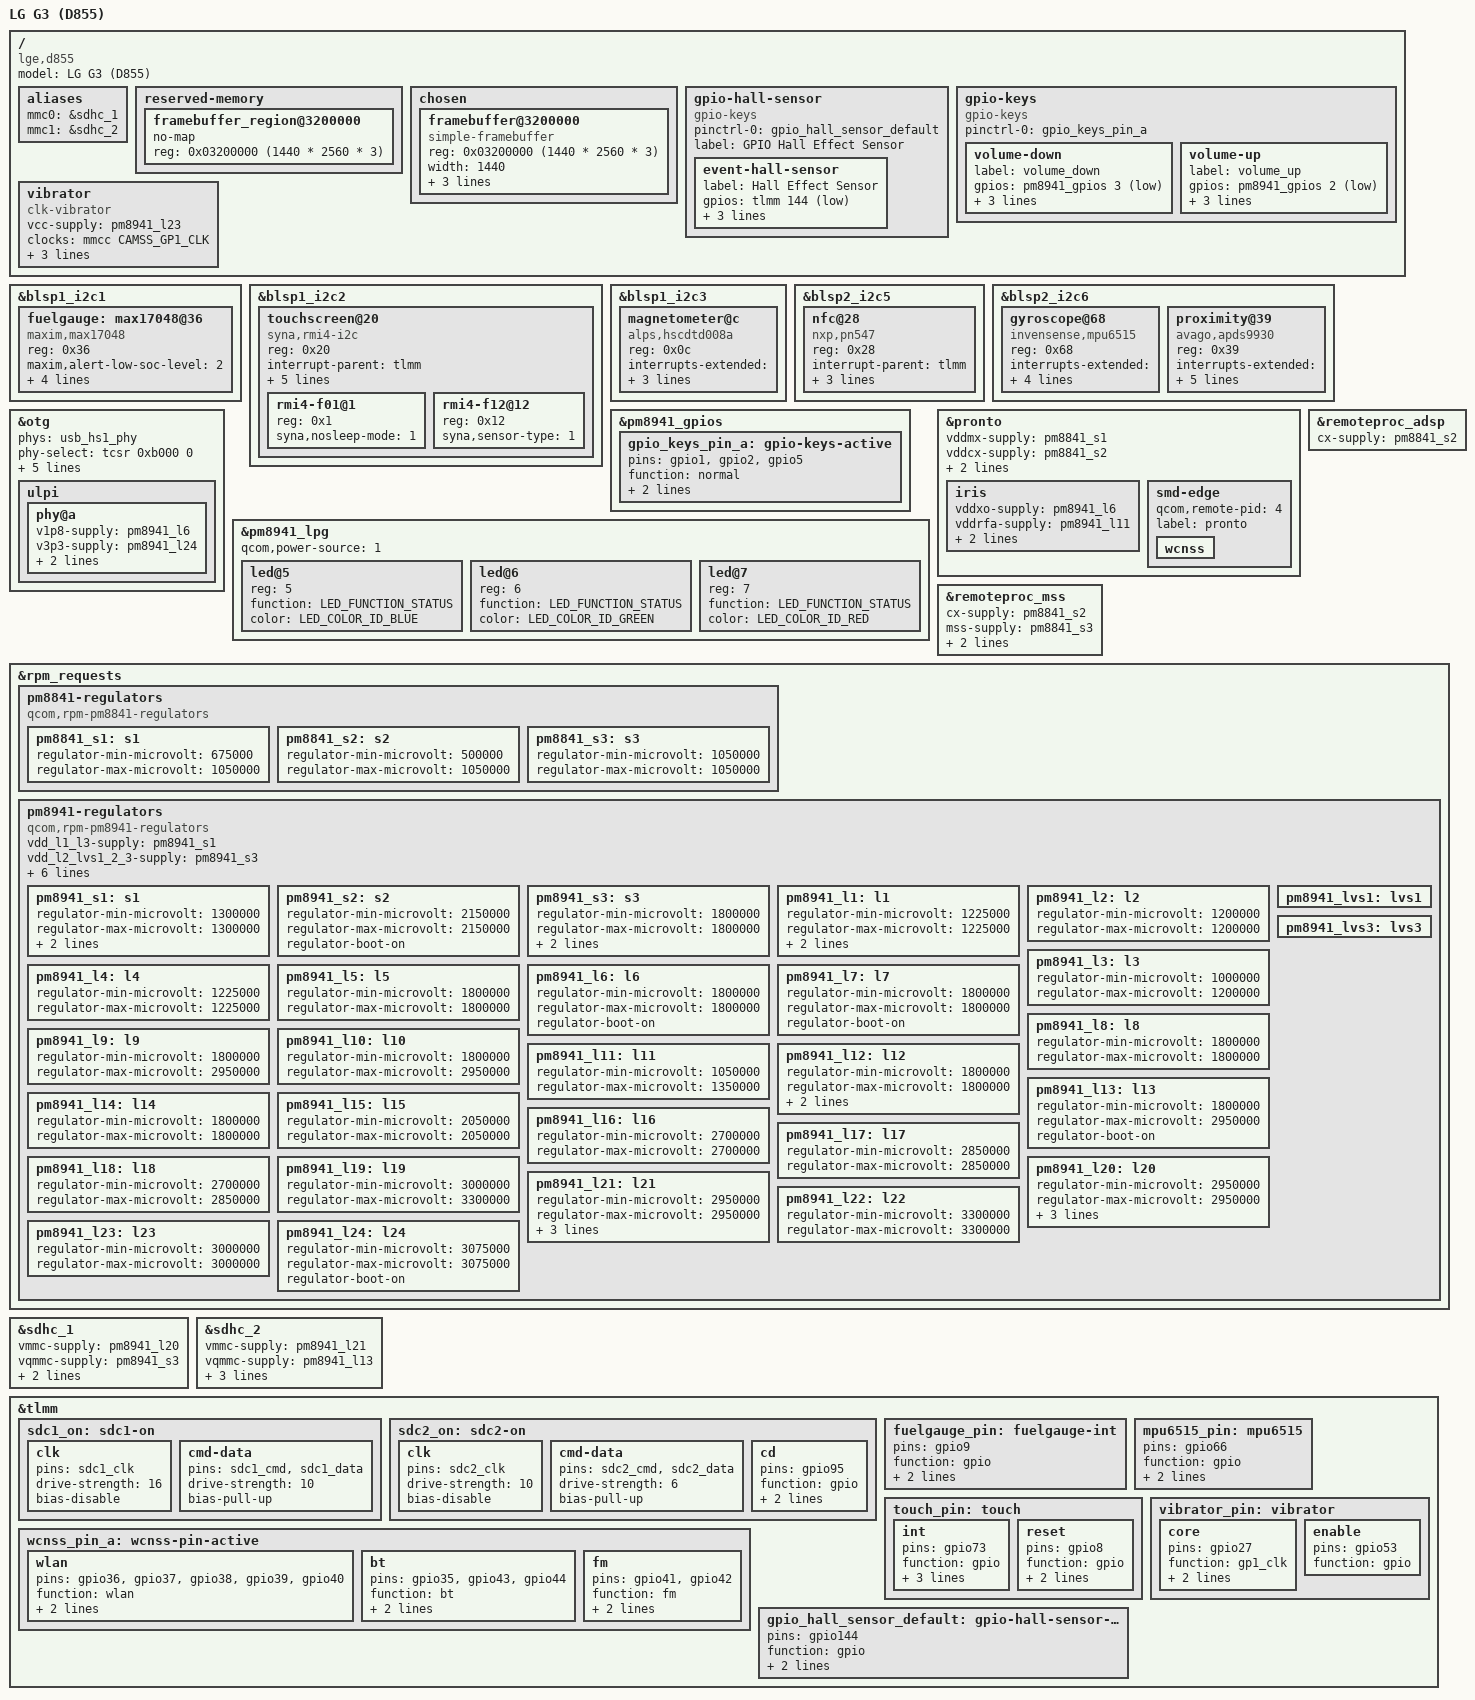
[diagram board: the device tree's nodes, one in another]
// SPDX-License-Identifier: GPL-2.0
#include "qcom-msm8974pro.dtsi"
#include "qcom-pm8841.dtsi"
#include "qcom-pm8941.dtsi"
#include <dt-bindings/input/input.h>
#include <dt-bindings/leds/common.h>
#include <dt-bindings/pinctrl/qcom,pmic-gpio.h>

/ {
	model = "LG G3 (D855)";
	compatible = "lge,d855", "qcom,msm8974";

	aliases {
		mmc0 = &sdhc_1;
		mmc1 = &sdhc_2;
	};

	reserved-memory {
		#address-cells = <1>;
		#size-cells = <1>;
		ranges;

		framebuffer_region@3200000 {
			no-map;
			reg = <0x03200000 (1440 * 2560 * 3)>;
		};
	};

	chosen {
		#address-cells = <1>;
		#size-cells = <1>;
		ranges;

		framebuffer@3200000 {
			compatible = "simple-framebuffer";
			reg = <0x03200000 (1440 * 2560 * 3)>;
			width = <1440>;
			height = <2560>;
			stride = <(1440 * 3)>;
			format = "r8g8b8";
		};
	};

	gpio-hall-sensor {
		compatible = "gpio-keys";

		pinctrl-names = "default";
		pinctrl-0 = <&gpio_hall_sensor_default>;

		label = "GPIO Hall Effect Sensor";

		event-hall-sensor {
			label = "Hall Effect Sensor";
			gpios = <&tlmm 144 GPIO_ACTIVE_LOW>;
			linux,input-type = <EV_SW>;
			linux,code = <SW_LID>;
			linux,can-disable;
		};
	};

	gpio-keys {
		compatible = "gpio-keys";

		pinctrl-names = "default";
		pinctrl-0 = <&gpio_keys_pin_a>;

		volume-down {
			label = "volume_down";
			gpios = <&pm8941_gpios 3 GPIO_ACTIVE_LOW>;
			linux,code = <KEY_VOLUMEDOWN>;
			wakeup-source;
			debounce-interval = <15>;
		};

		volume-up {
			label = "volume_up";
			gpios = <&pm8941_gpios 2 GPIO_ACTIVE_LOW>;
			linux,code = <KEY_VOLUMEUP>;
			wakeup-source;
			debounce-interval = <15>;
		};
	};

	vibrator {
		compatible = "clk-vibrator";

		vcc-supply = <&pm8941_l23>;

		clocks = <&mmcc CAMSS_GP1_CLK>;
		clock-names = "core";
		clock-frequency = <29813>;

		enable-gpios = <&tlmm 53 GPIO_ACTIVE_HIGH>;

		pinctrl-names = "default";
		pinctrl-0 = <&vibrator_pin>;
	};
};

&blsp1_i2c1 {
	status = "okay";

	fuelgauge: max17048@36 {
		compatible = "maxim,max17048";
		reg = <0x36>;
		maxim,alert-low-soc-level = <2>;
		maxim,double-soc;
		maxim,rcomp = /bits/ 8 <0x67>;

		interrupts-extended = <&tlmm 9 IRQ_TYPE_LEVEL_LOW>;

		pinctrl-names = "default";
		pinctrl-0 = <&fuelgauge_pin>;
	};
};

&blsp1_i2c2 {
	status = "okay";

	touchscreen@20 {
		compatible = "syna,rmi4-i2c";
		reg = <0x20>;

		interrupt-parent = <&tlmm>;
		interrupts = <73 IRQ_TYPE_EDGE_FALLING>;

		vdd-supply = <&pm8941_l22>;
		vio-supply = <&pm8941_lvs3>;
		
		syna,startup-delay-ms = <10>;

		pinctrl-names = "default";
		pinctrl-0 = <&touch_pin>;

		#address-cells = <1>;
		#size-cells = <0>;

		rmi4-f01@1 {
			reg = <0x1>;
			syna,nosleep-mode = <1>;
		};

		rmi4-f12@12 {
			reg = <0x12>;
			syna,sensor-type = <1>;
		};
	};
};

&blsp1_i2c3 {
	status = "okay";

	magnetometer@c {
		compatible = "alps,hscdtd008a";
		reg = <0x0c>;
		interrupts-extended = <&tlmm 67 IRQ_TYPE_EDGE_RISING>;
		dvdd-supply = <&pm8941_lvs1>;
		avdd-supply = <&pm8941_l17>;

		/* Add mount matrix here */
	};
};

&blsp2_i2c5 {
	status = "okay";

	nfc@28 {
		compatible = "nxp,pn547", "nxp,nxp-nci-i2c";

		reg = <0x28>;

		interrupt-parent = <&tlmm>;
		interrupts = <5 IRQ_TYPE_EDGE_RISING>;

		enable-gpios = <&tlmm 94 GPIO_ACTIVE_HIGH>;
		firmware-gpios = <&tlmm 92 GPIO_ACTIVE_HIGH>;
	};
};

&blsp2_i2c6 {
	status = "okay";

	#address-cells = <1>;
	#size-cells = <0>;

	gyroscope@68 {
		compatible = "invensense,mpu6515";
		reg = <0x68>;
		interrupts-extended = <&tlmm 66 IRQ_TYPE_EDGE_FALLING>;
		vddio-supply = <&pm8941_lvs1>;
		vdd-supply = <&pm8941_l17>;

		pinctrl-names = "default";
		pinctrl-0 = <&mpu6515_pin>;

		/* Add mount matrix here */
	};

	proximity@39 {
		compatible = "avago,apds9930";
		reg = <0x39>;
		interrupts-extended = <&tlmm 102 IRQ_TYPE_EDGE_FALLING>;
		vddio-supply = <&pm8941_lvs1>;
		vdd-supply = <&pm8941_l17>;
		led-max-microamp = <100000>;
		amstaos,proximity-diodes = <1>;
	};
};

&otg {
	status = "okay";

	phys = <&usb_hs1_phy>;
	phy-select = <&tcsr 0xb000 0>;
	extcon = <&smbb>, <&usb_id>;
	vbus-supply = <&chg_otg>;

	hnp-disable;
	srp-disable;
	adp-disable;

	ulpi {
		phy@a {
			status = "okay";

			v1p8-supply = <&pm8941_l6>;
			v3p3-supply = <&pm8941_l24>;

			extcon = <&smbb>;
			qcom,init-seq = /bits/ 8 <0x1 0x64>;
		};
	};
};

&pm8941_gpios {
	gpio_keys_pin_a: gpio-keys-active {
		pins = "gpio1", "gpio2", "gpio5";
		function = "normal";

		bias-pull-up;
		power-source = <PM8941_GPIO_S3>;
	};
};

&pm8941_lpg {
	status = "okay";

	#address-cells = <1>;
	#size-cells = <0>;

	qcom,power-source = <1>;

	led@5 {
		reg = <5>;
		function = LED_FUNCTION_STATUS;
		color = <LED_COLOR_ID_BLUE>;
	};

	led@6 {
		reg = <6>;
		function = LED_FUNCTION_STATUS;
		color = <LED_COLOR_ID_GREEN>;
	};

	led@7 {
		reg = <7>;
		function = LED_FUNCTION_STATUS;
		color = <LED_COLOR_ID_RED>;
	};
};

&pronto {
	status = "okay";

	vddmx-supply = <&pm8841_s1>;
	vddcx-supply = <&pm8841_s2>;
	vddpx-supply = <&pm8941_s3>;

	pinctrl-names = "default";
	pinctrl-0 = <&wcnss_pin_a>;

	iris {
		vddxo-supply = <&pm8941_l6>;
		vddrfa-supply = <&pm8941_l11>;
		vddpa-supply = <&pm8941_l19>;
		vdddig-supply = <&pm8941_s3>;
	};

	smd-edge {
		qcom,remote-pid = <4>;
		label = "pronto";

		wcnss {
			status = "okay";
		};
	};
};

&remoteproc_adsp {
	status = "okay";
	cx-supply = <&pm8841_s2>;
};

&remoteproc_mss {
	status = "okay";
	cx-supply = <&pm8841_s2>;
	mss-supply = <&pm8841_s3>;
	mx-supply = <&pm8841_s1>;
	pll-supply = <&pm8941_l12>;
};

&rpm_requests {
	pm8841-regulators {
		compatible = "qcom,rpm-pm8841-regulators";

		pm8841_s1: s1 {
			regulator-min-microvolt = <675000>;
			regulator-max-microvolt = <1050000>;
		};

		pm8841_s2: s2 {
			regulator-min-microvolt = <500000>;
			regulator-max-microvolt = <1050000>;
		};

		pm8841_s3: s3 {
			regulator-min-microvolt = <1050000>;
			regulator-max-microvolt = <1050000>;
		};
	};

	pm8941-regulators {
		compatible = "qcom,rpm-pm8941-regulators";

		vdd_l1_l3-supply = <&pm8941_s1>;
		vdd_l2_lvs1_2_3-supply = <&pm8941_s3>;
		vdd_l4_l11-supply = <&pm8941_s1>;
		vdd_l5_l7-supply = <&pm8941_s2>;
		vdd_l6_l12_l14_l15-supply = <&pm8941_s2>;
		vdd_l9_l10_l17_l22-supply = <&vreg_boost>;
		vdd_l13_l20_l23_l24-supply = <&vreg_boost>;
		vdd_l21-supply = <&vreg_boost>;

		pm8941_s1: s1 {
			regulator-min-microvolt = <1300000>;
			regulator-max-microvolt = <1300000>;
			regulator-always-on;
			regulator-boot-on;
		};

		pm8941_s2: s2 {
			regulator-min-microvolt = <2150000>;
			regulator-max-microvolt = <2150000>;
			regulator-boot-on;
		};

		pm8941_s3: s3 {
			regulator-min-microvolt = <1800000>;
			regulator-max-microvolt = <1800000>;
			regulator-always-on;
			regulator-boot-on;
		};

		pm8941_l1: l1 {
			regulator-min-microvolt = <1225000>;
			regulator-max-microvolt = <1225000>;
			regulator-always-on;
			regulator-boot-on;
		};

		pm8941_l2: l2 {
			regulator-min-microvolt = <1200000>;
			regulator-max-microvolt = <1200000>;
		};

		pm8941_l3: l3 {
			regulator-min-microvolt = <1000000>;
			regulator-max-microvolt = <1200000>;
		};

		pm8941_l4: l4 {
			regulator-min-microvolt = <1225000>;
			regulator-max-microvolt = <1225000>;
		};

		pm8941_l5: l5 {
			regulator-min-microvolt = <1800000>;
			regulator-max-microvolt = <1800000>;
		};

		pm8941_l6: l6 {
			regulator-min-microvolt = <1800000>;
			regulator-max-microvolt = <1800000>;
			regulator-boot-on;
		};

		pm8941_l7: l7 {
			regulator-min-microvolt = <1800000>;
			regulator-max-microvolt = <1800000>;
			regulator-boot-on;
		};

		pm8941_l8: l8 {
			regulator-min-microvolt = <1800000>;
			regulator-max-microvolt = <1800000>;
		};

		pm8941_l9: l9 {
			regulator-min-microvolt = <1800000>;
			regulator-max-microvolt = <2950000>;
		};

		pm8941_l10: l10 {
			regulator-min-microvolt = <1800000>;
			regulator-max-microvolt = <2950000>;
		};

		pm8941_l11: l11 {
			regulator-min-microvolt = <1050000>;
			regulator-max-microvolt = <1350000>;
		};

		pm8941_l12: l12 {
			regulator-min-microvolt = <1800000>;
			regulator-max-microvolt = <1800000>;
			regulator-always-on;
			regulator-boot-on;
		};

		pm8941_l13: l13 {
			regulator-min-microvolt = <1800000>;
			regulator-max-microvolt = <2950000>;
			regulator-boot-on;
		};

		pm8941_l14: l14 {
			regulator-min-microvolt = <1800000>;
			regulator-max-microvolt = <1800000>;
		};

		pm8941_l15: l15 {
			regulator-min-microvolt = <2050000>;
			regulator-max-microvolt = <2050000>;
		};

		pm8941_l16: l16 {
			regulator-min-microvolt = <2700000>;
			regulator-max-microvolt = <2700000>;
		};

		pm8941_l17: l17 {
			regulator-min-microvolt = <2850000>;
			regulator-max-microvolt = <2850000>;
		};

		pm8941_l18: l18 {
			regulator-min-microvolt = <2700000>;
			regulator-max-microvolt = <2850000>;
		};

		pm8941_l19: l19 {
			regulator-min-microvolt = <3000000>;
			regulator-max-microvolt = <3300000>;
		};

		pm8941_l20: l20 {
			regulator-min-microvolt = <2950000>;
			regulator-max-microvolt = <2950000>;
			regulator-system-load = <200000>;
			regulator-allow-set-load;
			regulator-boot-on;
		};

		pm8941_l21: l21 {
			regulator-min-microvolt = <2950000>;
			regulator-max-microvolt = <2950000>;
			regulator-system-load = <150000>;
			regulator-allow-set-load;
			regulator-boot-on;
		};

		pm8941_l22: l22 {
			regulator-min-microvolt = <3300000>;
			regulator-max-microvolt = <3300000>;
		};

		pm8941_l23: l23 {
			regulator-min-microvolt = <3000000>;
			regulator-max-microvolt = <3000000>;
		};

		pm8941_l24: l24 {
			regulator-min-microvolt = <3075000>;
			regulator-max-microvolt = <3075000>;
			regulator-boot-on;
		};
		
		pm8941_lvs1: lvs1 {};
		pm8941_lvs3: lvs3 {};
	};
};

&sdhc_1 {
	status = "okay";

	vmmc-supply = <&pm8941_l20>;
	vqmmc-supply = <&pm8941_s3>;

	pinctrl-names = "default", "sleep";
	pinctrl-0 = <&sdc1_on>;
	pinctrl-1 = <&sdc1_off>;
};

&sdhc_2 {
	status = "okay";

	vmmc-supply = <&pm8941_l21>;
	vqmmc-supply = <&pm8941_l13>;
	
	cd-gpios = <&tlmm 95 GPIO_ACTIVE_LOW>;
	
	pinctrl-names = "default", "sleep";
	pinctrl-0 = <&sdc2_on>;
	pinctrl-1 = <&sdc2_off>;
};

&tlmm {
	sdc1_on: sdc1-on {
		clk {
			pins = "sdc1_clk";
			drive-strength = <16>;
			bias-disable;
		};

		cmd-data {
			pins = "sdc1_cmd", "sdc1_data";
			drive-strength = <10>;
			bias-pull-up;
		};
	};

	sdc2_on: sdc2-on {
		clk {
			pins = "sdc2_clk";
			drive-strength = <10>;
			bias-disable;
		};

		cmd-data {
			pins = "sdc2_cmd", "sdc2_data";
			drive-strength = <6>;
			bias-pull-up;
		};
		
		cd {
			pins = "gpio95";
			function = "gpio";
			drive-strength = <2>;
			bias-disable;
		};
	};

	wcnss_pin_a: wcnss-pin-active {
		wlan {
			pins =  "gpio36", "gpio37", "gpio38", "gpio39", "gpio40";
			function = "wlan";

			drive-strength = <6>;
			bias-pull-down;
		};

		bt {
			pins = "gpio35", "gpio43", "gpio44";
			function = "bt";

			drive-strength = <2>;
			bias-pull-down;
		};

		fm {
			pins = "gpio41", "gpio42";
			function = "fm";

			drive-strength = <2>;
			bias-pull-down;
		};
	};

	fuelgauge_pin: fuelgauge-int {
		pins = "gpio9";
		function = "gpio";

		bias-disable;
		input-enable;
	};

	mpu6515_pin: mpu6515 {
		pins = "gpio66";
		function = "gpio";
		bias-disable;
		input-enable;
	};

	touch_pin: touch {
		int {
			pins = "gpio73";
			function = "gpio";

			drive-strength = <2>;
			bias-disable;
			input-enable;
	};

		reset {
			pins = "gpio8";
			function = "gpio";

			drive-strength = <2>;
			bias-pull-up;
		};
	};
	
	gpio_hall_sensor_default: gpio-hall-sensor-default {
		pins = "gpio144";
		function = "gpio";

		drive-strength = <2>;
		bias-disable;
	};

	vibrator_pin: vibrator {
		core {
			pins = "gpio27";
			function = "gp1_clk";

			drive-strength = <6>;
			bias-disable;
		};

		enable {
			pins = "gpio53";
			function = "gpio";
		};
	};
};
